# RX64M_MTU8_Pilot register map
File version: 1.0
RX64M_MTU8_Pilot peripheral registers generated from iodefine.h (pilot).
Registers are 8-bit, read-write, reset 0x0 unless marked. A register's access mark holds for its fields unless they carry their own. Offsets are from the block's base; lines under a group give offsets from that group; [hi:lo] are bit positions; {n}, {i} and the like mark numbered series; 'fields as' and 'values as' point back to an identical list; <NAME> marks a mode.

## Memory map
0x000C1298 MTU8 size 0x384

## MTU8
Base 0x000C1298
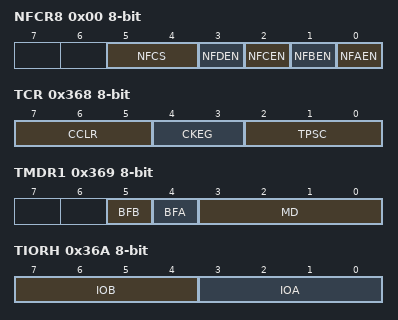
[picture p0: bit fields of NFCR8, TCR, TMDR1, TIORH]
0x00 NFCR8
  [5:4] NFCS, [3] NFDEN, [2] NFCEN, [1] NFBEN, [0] NFAEN
0x368 TCR
  [7:5] CCLR, [4:3] CKEG, [2:0] TPSC
0x369 TMDR1
  [5] BFB, [4] BFA, [3:0] MD
0x36A TIORH
  [7:4] IOB, [3:0] IOA
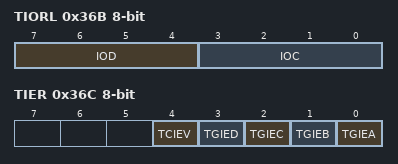
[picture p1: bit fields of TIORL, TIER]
0x36B TIORL
  [7:4] IOD, [3:0] IOC
0x36C TIER
  [4] TCIEV, [3] TGIED, [2] TGIEC, [1] TGIEB, [0] TGIEA
0x36E TCR2
  [2:0] TPSC2
0x370 TCNT 32-bit
0x374 TGRA 32-bit reset 0xFFFFFFFF
0x378 TGRB 32-bit reset 0xFFFFFFFF
0x37C TGRC 32-bit reset 0xFFFFFFFF
0x380 TGRD 32-bit reset 0xFFFFFFFF
